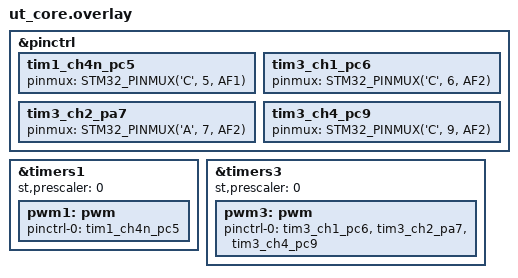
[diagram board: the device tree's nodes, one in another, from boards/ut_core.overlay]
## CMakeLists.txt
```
cmake_minimum_required(VERSION 3.20.0)

set(BOARD ut_core)

find_package(Zephyr REQUIRED HINTS $ENV{ZEPHYR_BASE})
project(solar_main)

target_sources(app PRIVATE src/demo.c)
#target_sources(app PRIVATE src/main.c)
# target_include_directories(app PRIVATE ${ROOT}/core)
target_include_directories(app PRIVATE $ENV{ROOT}/core)
```

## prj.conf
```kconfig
CONFIG_GPIO=y
CONFIG_CAN=y
CONFIG_CAN_STM32_FDCAN=y

# --- LOGGING & CONSOLE SETUP (RTT) ---
# 1. Force the Console subsystem to stay ON
CONFIG_CONSOLE=y
CONFIG_STDOUT_CONSOLE=y

# 2. Configure RTT as the backend
CONFIG_USE_SEGGER_RTT=y
CONFIG_RTT_CONSOLE=y

# 3. Disable UART/Serial to prevent conflicts
CONFIG_UART_CONSOLE=n
CONFIG_SERIAL=n

# 4. Connect Printk and Logging to RTT
CONFIG_PRINTK=y
CONFIG_LOG=y
CONFIG_LOG_BACKEND_RTT=y
CONFIG_LOG_BACKEND_UART=n
CONFIG_LOG_MODE_IMMEDIATE=y

CONFIG_NEWLIB_LIBC=y
CONFIG_NEWLIB_LIBC_FLOAT_PRINTF=y

CONFIG_PWM=y
```

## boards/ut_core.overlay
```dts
#include <zephyr/dt-bindings/pwm/pwm.h>
#include <zephyr/dt-bindings/pinctrl/stm32-pinctrl.h>

/*
 * Solarconglomerator PWM overlay — STM32U5A5
 *
 * PC5 = TIM1_CH4N (AF1) — complementary, needs MOE+CC4NE in code
 * PC6 = TIM3_CH1  (AF2)
 * PA7 = TIM3_CH2  (AF2)
 * PC9 = TIM3_CH4  (AF2)
 */

&pinctrl {
	/* TIM1 complementary output */
	tim1_ch4n_pc5: tim1_ch4n_pc5 {
		pinmux = <STM32_PINMUX('C', 5, AF1)>;
	};

	/* TIM3 channels */
	tim3_ch1_pc6: tim3_ch1_pc6 {
		pinmux = <STM32_PINMUX('C', 6, AF2)>;
	};

	tim3_ch2_pa7: tim3_ch2_pa7 {
		pinmux = <STM32_PINMUX('A', 7, AF2)>;
	};

	tim3_ch4_pc9: tim3_ch4_pc9 {
		pinmux = <STM32_PINMUX('C', 9, AF2)>;
	};
};

&timers1 {
	status = "okay";
	st,prescaler = <0>;

	pwm1: pwm {
		status = "okay";
		pinctrl-0 = <&tim1_ch4n_pc5>;
		pinctrl-names = "default";
	};
};

&timers3 {
	status = "okay";
	st,prescaler = <0>;

	pwm3: pwm {
		status = "okay";
		pinctrl-0 = <&tim3_ch1_pc6 &tim3_ch2_pa7 &tim3_ch4_pc9>;
		pinctrl-names = "default";
	};
};
```

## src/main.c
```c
#include <zephyr/kernel.h>
#include <zephyr/device.h>
#include <zephyr/devicetree.h>
#include <zephyr/drivers/gpio.h>
#include <zephyr/drivers/pwm.h>
#include <zephyr/sys/printk.h>

#include <stm32_ll_tim.h>

/* Mux enable */
static const struct device *const gpioa = DEVICE_DT_GET(DT_NODELABEL(gpioa));

/* PWM devices */
static const struct device *const pwm1_dev = DEVICE_DT_GET(DT_NODELABEL(pwm1));
static const struct device *const pwm3_dev = DEVICE_DT_GET(DT_NODELABEL(pwm3));

#define PWM_FREQ    20000U
#define PWM_PERIOD  PWM_HZ(PWM_FREQ)

/* Channel numbers */
#define TIM1_CH4    4U
#define TIM3_CH1    1U
#define TIM3_CH2    2U
#define TIM3_CH4    4U

/* Enable TIM1 complementary output for CH4N on PC5 */
static void tim1_enable_ch4n(void)
{
	TIM1->CCER |= TIM_CCER_CC4NE | TIM_CCER_CC4E;
	TIM1->BDTR |= TIM_BDTR_MOE;
}

/* Set all 4 channels to the same duty cycle */
static void set_all_duty(uint32_t duty_percent)
{
	uint32_t pulse_tim = ((uint64_t)PWM_PERIOD * duty_percent) / 100U;
	uint32_t pulse_inv = PWM_PERIOD - pulse_tim;  /* inverted for CH4N */

	/* PC5: TIM1_CH4N — complementary, so invert */
	pwm_set(pwm1_dev, TIM1_CH4, PWM_PERIOD, pulse_inv, PWM_POLARITY_NORMAL);
	TIM1->CCER |= TIM_CCER_CC4NE | TIM_CCER_CC4E;
	TIM1->BDTR |= TIM_BDTR_MOE;

	/* PC6: TIM3_CH1 */
	pwm_set(pwm3_dev, TIM3_CH1, PWM_PERIOD, pulse_tim, PWM_POLARITY_NORMAL);

	/* PA7: TIM3_CH2 */
	pwm_set(pwm3_dev, TIM3_CH2, PWM_PERIOD, pulse_tim, PWM_POLARITY_NORMAL);

	/* PC9: TIM3_CH4 */
	pwm_set(pwm3_dev, TIM3_CH4, PWM_PERIOD, pulse_tim, PWM_POLARITY_NORMAL);
}

int main(void)
{
	int ret;

	printk("\n=== Solarconglomerator PWM Test (4 channels) ===\n");

	/* PA5: mux enable */
	if (!device_is_ready(gpioa)) {
		printk("ERROR: GPIOA not ready!\n");
		return 0;
	}
	gpio_pin_configure(gpioa, 5, GPIO_OUTPUT_ACTIVE);
	gpio_pin_set(gpioa, 5, 0);
	printk("PA5: mux enable LOW\n");

    // const struct device *const gpioc = DEVICE_DT_GET(DT_NODELABEL(gpioc));
    // gpio_pin_configure(gpioc, 2, GPIO_OUTPUT_INACTIVE);
    // gpio_pin_configure(gpioc, 3, GPIO_OUTPUT_INACTIVE);
    // gpio_pin_configure(gpioc, 4, GPIO_OUTPUT_INACTIVE);
    // gpio_pin_set(gpioc, 2, 0);
    // gpio_pin_set(gpioc, 3, 0);
    // gpio_pin_set(gpioc, 4, 0);

	/* Check devices */
	if (!device_is_ready(pwm1_dev)) {
		printk("ERROR: TIM1 PWM not ready!\n");
		return 0;
	}
	if (!device_is_ready(pwm3_dev)) {
		printk("ERROR: TIM3 PWM not ready!\n");
		return 0;
	}

	/* --- Set all channels to 50% --- */
	uint32_t half = PWM_PERIOD / 2;

	/* PC5: TIM1_CH4N */
	ret = pwm_set(pwm1_dev, TIM1_CH4, PWM_PERIOD, half, PWM_POLARITY_NORMAL);
	tim1_enable_ch4n();
	printk("PC5 TIM1_CH4N: %s\n", ret ? "FAIL" : "OK");

	/* PC6: TIM3_CH1 */
	ret = pwm_set(pwm3_dev, TIM3_CH1, PWM_PERIOD, half, PWM_POLARITY_NORMAL);
	printk("PC6 TIM3_CH1:  %s\n", ret ? "FAIL" : "OK");

	/* PA7: TIM3_CH2 */
	ret = pwm_set(pwm3_dev, TIM3_CH2, PWM_PERIOD, half, PWM_POLARITY_NORMAL);
	printk("PA7 TIM3_CH2:  %s\n", ret ? "FAIL" : "OK");

	/* PC9: TIM3_CH4 */
	ret = pwm_set(pwm3_dev, TIM3_CH4, PWM_PERIOD, half, PWM_POLARITY_NORMAL);
	printk("PC9 TIM3_CH4:  %s\n", ret ? "FAIL" : "OK");

	printk("\nAll channels at 50%% -- verify with scope.\n");
	printk("Sweep starts in 5 s ...\n\n");
	k_msleep(5000);

	/* Sweep all channels together */
	while (1) {
		for (int duty = 0; duty <= 100; duty += 5) {
			set_all_duty(duty);
			printk("duty=%3d%%\n", duty);
			k_msleep(8000);
		}

		for (int duty = 100; duty >= 0; duty -= 5) {
			set_all_duty(duty);
			printk("duty=%3d%%\n", duty);
			k_msleep(8000);
		}
	}
	return 0;
}
```
